VERSION ""

NS_ :

BS_:

BO_ 129 steering: 8 ElectricPowerSteering
 SG_ SteeringAngle : 23|16@0- (1,0) [0|0] "deg" Vector__XXX

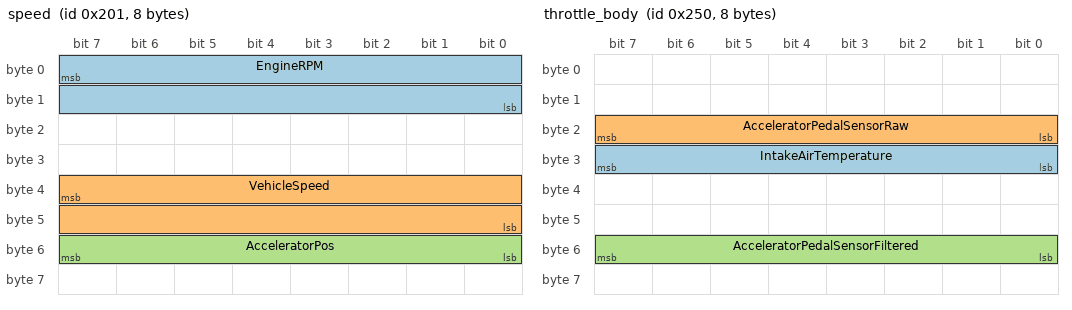
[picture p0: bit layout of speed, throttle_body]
BO_ 513 speed: 8 PowertrainControlModule
 SG_ EngineRPM : 7|16@0+ (0.25,0) [0|0] "rpm" Vector__XXX
 SG_ VehicleSpeed : 39|16@0+ (0.01,-100) [0|0] "kph" Vector__XXX
 SG_ AcceleratorPos : 55|8@0+ (0.5,0) [0|0] "%" Vector__XXX

BO_ 592 throttle_body: 8 PowertrainControlModule
 SG_ IntakeAirTemperature : 31|8@0+ (1,-40) [0|0] "Cel" Vector__XXX
 SG_ AcceleratorPedalSensorRaw : 23|8@0+ (1,0) [0|0] "" Vector__XXX
 SG_ AcceleratorPedalSensorFiltered : 55|8@0+ (1,0) [0|0] "" Vector__XXX

BO_ 658 brake_controls: 8 PowertrainControlModule
 SG_ BrakePedalSwitch : 43|1@1+ (1,0) [0|0] "" Vector__XXX
 SG_ ParkingBrakeSwitch : 38|1@1+ (1,0) [0|0] "" Vector__XXX

BO_ 1056 coolant: 8 PowertrainControlModule
 SG_ CoolantTemperature : 7|8@0+ (1,-40) [0|0] "Cel" Vector__XXX

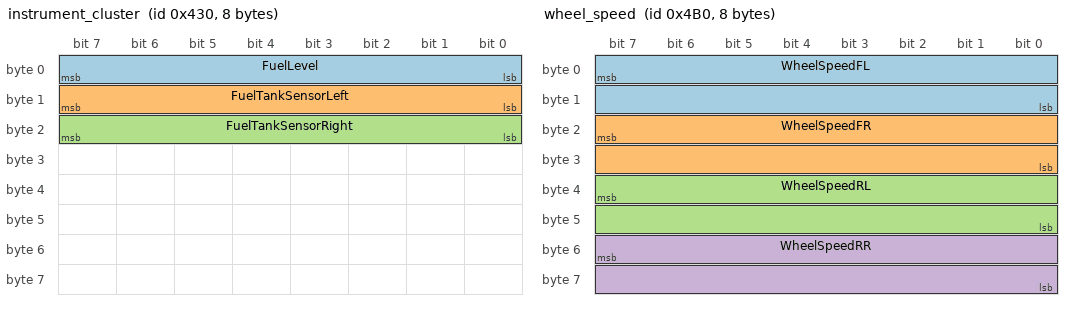
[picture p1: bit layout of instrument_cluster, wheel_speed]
BO_ 1072 instrument_cluster: 8 InstrumentCluster
 SG_ FuelLevel : 7|8@0+ (0.392156,0) [0|0] "%" Vector__XXX
 SG_ FuelTankSensorLeft : 15|8@0+ (1,0) [0|0] "" Vector__XXX
 SG_ FuelTankSensorRight : 23|8@0+ (1,0) [0|0] "" Vector__XXX

BO_ 1200 wheel_speed: 8 AntilockBrakeSystem
 SG_ WheelSpeedFL : 7|16@0+ (0.01,-100) [0|0] "kph" Vector__XXX
 SG_ WheelSpeedFR : 23|16@0+ (0.01,-100) [0|0] "kph" Vector__XXX
 SG_ WheelSpeedRL : 39|16@0+ (0.01,-100) [0|0] "kph" Vector__XXX
 SG_ WheelSpeedRR : 55|16@0+ (0.01,-100) [0|0] "kph" Vector__XXX

BU_: XXX

CM_ "AUTOGENERATED FILE, DO NOT EDIT";

CM_ "Imported file _comma.dbc starts here";
CM_ "Imported file _honda_common.dbc starts here";
CM_ SG_ 304 "Seems to be platform-agnostic";
CM_ SG_ 316 "Should exist on Nidec";
CM_ SG_ 420 BRAKE_HOLD_RELATED "On when Brake Hold engaged";
CM_ SG_ 490 LONG_ACCEL "wheel speed derivative, noisy and zero snapping";
CM_ SG_ 773 PASS_AIRBAG_ON "Might just be indicator light";
CM_ SG_ 773 PASS_AIRBAG_OFF "Might just be indicator light";
CM_ SG_ 780 CRUISE_SPEED "255 = no speed";
CM_ SG_ 780 PCM_SPEED "Used by Nidec";
CM_ SG_ 780 PCM_GAS "Used by Nidec";
CM_ SG_ 804 CRUISE_SPEED_PCM "255 = no speed";

CM_ "Imported file _nidec_common.dbc starts here";
CM_ SG_ 506 AEB_REQ_1 "set for duration of suspected AEB event";
CM_ SG_ 506 COMPUTER_BRAKE_ALT "Used by dual-can Nidec";
CM_ SG_ 506 BRAKE_PUMP_REQUEST_ALT "Used by dual-can Nidec";
CM_ SG_ 829 BEEP "beeps are pleasant, chimes are for warnngs etc...";

CM_ "honda_fit_hybrid_2018_can.dbc starts here";

CM_ SG_ 419 GEAR "10 = reverse, 11 = transition";

VAL_ 262 DI_torqueDriver -4096 "SNA" ;
VAL_ 262 DI_torqueMotor -4096 "SNA" ;
VAL_ 262 DI_soptState 7 "SOPT_TEST_SNA" 4 "SOPT_TEST_NOT_RUN" 3 "SOPT_TEST_PASSED" 2 "SOPT_TEST_FAILED" 1 "SOPT_TEST_IN_PROGRESS" 0 "SOPT_PRE_TEST" ;
VAL_ 262 DI_motorRPM -32768 "SNA" ;
VAL_ 262 DI_pedalPos 255 "SNA" ;
VAL_ 278 DI_torqueEstimate -2048 "SNA" ;
VAL_ 278 DI_gear 7 "DI_GEAR_SNA" 4 "DI_GEAR_D" 3 "DI_GEAR_N" 2 "DI_GEAR_R" 1 "DI_GEAR_P" 0 "DI_GEAR_INVALID" ;
VAL_ 278 DI_brakePedal 1 "Applied" 0 "Not_applied" ;
VAL_ 278 DI_vehicleSpeed 4095 "SNA" ;
VAL_ 278 DI_gearRequest 7 "DI_GEAR_SNA" 4 "DI_GEAR_D" 3 "DI_GEAR_N" 2 "DI_GEAR_R" 1 "DI_GEAR_P" 0 "DI_GEAR_INVALID" ;
VAL_ 278 DI_torqueInterfaceFailure 1 "TORQUE_INTERFACE_FAILED" 0 "TORQUE_INTERFACE_NORMAL" ;
VAL_ 278 DI_brakePedalState 3 "SNA" 2 "INVALID" 1 "ON" 0 "OFF" ;
VAL_ 278 DI_epbParkRequest 1 "Park_requested" 0 "No_request" ;
VAL_ 278 DI_epbInterfaceReady 1 "EPB_INTERFACE_READY" 0 "EPB_INTERFACE_NOT_READY" ;
VAL_ 504 driverBrakeStatus 2 "APPLIED" 1 "NOT_APPLIED" ;
VAL_ 568 SpdCtrlLvr_Stat 32 "DN_1ST" 16 "UP_1ST" 8 "DN_2ND" 4 "UP_2ND" 2 "RWD" 1 "FWD" 0 "IDLE" ;
VAL_ 568 DTR_Dist_Rq 255 "SNA" 200 "ACC_DIST_7" 166 "ACC_DIST_6" 133 "ACC_DIST_5" 100 "ACC_DIST_4" 66 "ACC_DIST_3" 33 "ACC_DIST_2" 0 "ACC_DIST_1" ;
VAL_ 568 TurnIndLvr_Stat 3 "SNA" 2 "RIGHT" 1 "LEFT" 0 "IDLE" ;
VAL_ 568 HiBmLvr_Stat 3 "SNA" 2 "HIBM_FLSH_ON_PSD" 1 "HIBM_ON_PSD" 0 "IDLE" ;
VAL_ 568 WprWashSw_Psd 3 "SNA" 2 "WASH" 1 "TIPWIPE" 0 "NPSD" ;
VAL_ 568 WprWash_R_Sw_Posn_V2 3 "SNA" 2 "WASH" 1 "INTERVAL" 0 "OFF" ;
VAL_ 568 StW_Lvr_Stat 4 "STW_BACK" 3 "STW_FWD" 2 "STW_DOWN" 1 "STW_UP" 0 "NPSD" ;
VAL_ 568 StW_Cond_Psd 3 "SNA" 2 "DOWN" 1 "UP" 0 "NPSD" ;
VAL_ 568 HrnSw_Psd 3 "SNA" 2 "NDEF2" 1 "PSD" 0 "NPSD" ;
VAL_ 568 StW_Sw00_Psd 1 "PRESSED" 0 "NOT_PRESSED_SNA" ;
VAL_ 568 StW_Sw01_Psd 1 "PRESSED" 0 "NOT_PRESSED_SNA" ;
VAL_ 568 StW_Sw03_Psd 1 "PRESSED" 0 "NOT_PRESSED_SNA" ;
VAL_ 568 StW_Sw04_Psd 1 "PRESSED" 0 "NOT_PRESSED_SNA" ;
VAL_ 568 WprSw6Posn 7 "SNA" 6 "STAGE2" 5 "STAGE1" 4 "INTERVAL4" 3 "INTERVAL3" 2 "INTERVAL2" 1 "INTERVAL1" 0 "OFF" ;
VAL_ 598 DI_aebState 2 "ENABLED" 4 "FAULT" 7 "SNA" 1 "STANDBY" 3 "STANDSTILL" 0 "UNAVAILABLE" ;
VAL_ 598 DI_analogSpeed 4095 "SNA" ;
VAL_ 598 DI_cruiseState 2 "ENABLED" 5 "FAULT" 0 "OFF" 4 "OVERRIDE" 7 "PRE_CANCEL" 6 "PRE_FAULT" 1 "STANDBY" 3 "STANDSTILL" ;
VAL_ 598 DI_digitalSpeed 255 "SNA" ;
VAL_ 598 DI_immobilizerState 2 "AUTHENTICATING" 3 "DISARMED" 6 "FAULT" 4 "IDLE" 0 "INIT_SNA" 1 "REQUEST" 5 "RESET" ;
VAL_ 598 DI_speedUnits 1 "KPH" 0 "MPH" ;
VAL_ 598 DI_state 3 "ABORT" 4 "ENABLE" 2 "FAULT" 1 "STANDBY" 0 "UNAVAILABLE" ;
VAL_ 598 DI_systemState 3 "ABORT" 4 "ENABLE" 2 "FAULT" 1 "STANDBY" 0 "UNAVAILABLE" ;
VAL_ 598 DI_vehicleHoldState 2 "BLEND_IN" 4 "BLEND_OUT" 6 "FAULT" 7 "INIT" 5 "PARK" 1 "STANDBY" 3 "STANDSTILL" 0 "UNAVAILABLE" ;
VAL_ 703 DAS_setSpeed 4095 "SNA" ;
VAL_ 703 DAS_accState 15 "FAULT_SNA" 13 "ACC_CANCEL_GENERIC_SILENT" 11 "APC_SELFPARK_START" 10 "APC_UNPARK_COMPLETE" 9 "APC_PAUSE" 8 "APC_ABORT" 7 "APC_COMPLETE" 6 "APC_FORWARD" 5 "APC_BACKWARD" 4 "ACC_ON" 3 "ACC_HOLD" 0 "ACC_CANCEL_GENERIC" ;
VAL_ 703 DAS_aebEvent 3 "AEB_SNA" 2 "AEB_FAULT" 1 "AEB_ACTIVE" 0 "AEB_NOT_ACTIVE" ;
VAL_ 703 DAS_jerkMin 511 "SNA" ;
VAL_ 703 DAS_jerkMax 255 "SNA" ;
VAL_ 703 DAS_accelMin 511 "SNA" ;
